# A31G33x register map
Vendor: VENDOR ABOV Semiconductor Co., Ltd.; Series: A31G33x; File version: 1.0
CPU: CM0+ r0p1, little endian, no MPU, no FPU, VTOR, 2 interrupt priority bits
Registers are 32-bit, read-only, no defined reset value unless marked. A register's access mark holds for its fields unless they carry their own. Offsets are from the block's base; [hi:lo] are bit positions.

## SCULV — System Control Unit: LVI and LVR
Base 0x40005100
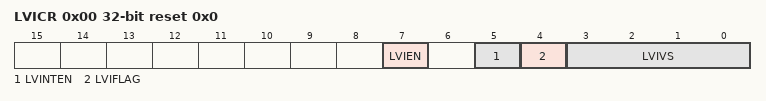
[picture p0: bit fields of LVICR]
0x00 LVICR rw reset 0x0 — Low Voltage Indicator Control Register
  [7] LVIEN — LVI Enable
    0=Disable low voltage indicator; 1=Enable low voltage indicator
  [5] LVINTEN — LVI Interrupt Enable
    0=Disable low voltage indicator interrupt; 1=Enable low voltage indicator interrupt
  [4] LVIFLAG — LVI Interrupt Flag
    0=No request occurred; 1=Request occurred
  [3:0] LVIVS — LVI Voltage Selection
    3=1p94 (1.94V); 4=2p03 (2.03V); 5=2p16V (2.16V); 6=2p35V (2.35V); 7=2p52V (2.52V); 8=2p72V (2.72V); 9=3p10V (3.10V); 10=3p24V (3.24V); 11=3p66V (3.66V); 12=3p79V (3.79V); 13=4p11V (4.11V); 14=4p28V (4.28V); 15=4p57V (4.57V)
0x04 LVRCR rw reset 0x0 — Low Voltage Reset Control Register
  [7:0] LVREN — LVR Enable
    85=Disable low voltage reset. (0x55); 0=Enable low voltage reset

## FMC — Flash Memory Controller
Base 0x40001B00
0x00 ADR rw reset 0x5FFFFF80 — Flash Memory Address Register
  [31:0] ADDR — Flash Memory Address Pointer
0x04 IDR1 rw reset 0x0 — Flash Memory Identification Register 1
  [31:0] ID1 — Flash Memory Identification 1
    0x8192A3B=Value (ID1 Value (0x08192a3b))
0x08 IDR2 rw reset 0x0 — Flash Memory Identification Register 2
  [31:0] ID2 — Flash Memory Identification 2
    0x4C5D6E7F=Value (ID2 Value (0x4c5d6e7f))
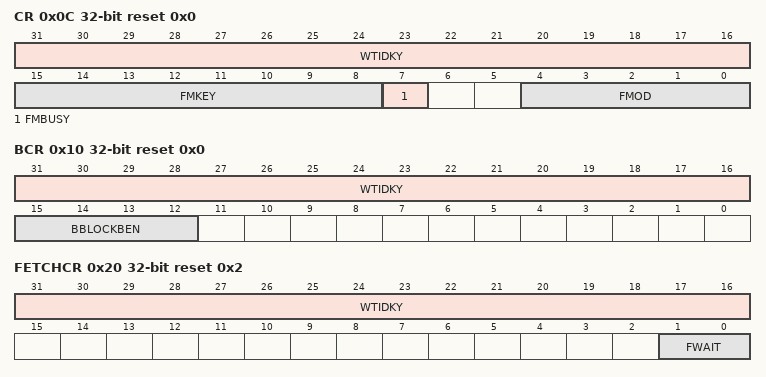
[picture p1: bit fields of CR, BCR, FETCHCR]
0x0C CR rw reset 0x0 — Flash Memory Control Register
  [31:16] WTIDKY wo — Write Identification Key (0x6c93)
    0x6C93=Value (Key Value (0x6c93))
  [15:8] FMKEY — Flash Memory Operation Area Selection
    0=NoSelect (Not select any area); 56=ConfigurationOptionArea (Select 'configure option area' for flash memory erase/write); 164=Flash (Select 'flash memory area' for flash memory erase/write)
  [7] FMBUSY ro — Flash Memory Operation Mode Busy
    0=NoEffect; 1=Busy
  [4:0] FMOD — Flash Memory Operation Mode Selection
    1=PageErase ('Flash page erase mode' and start when the flash operation rule is satisfied.); 2=SectorErase ('Flash sector erase mode' and start when the flash operation rule is satisfied.); 4=Write ('Flash write mode' and start when the flash operation rule is satisfied.); 8=BurstWrite ('Flash burst write mode' and start when the flash operation rule is satisfied.); 16=BulkErase ('Flash bulk erase mode' and start when the flash operation rule is satisfied.)
0x10 BCR rw reset 0x0 — Flash Memory Boot Protection Block Bulk Erase Control Register
  [31:16] WTIDKY wo — Write Identification Key (0xc1be)
    0xC1BE=Value (Key Value (0xc1be))
  [15:12] BBLOCKBEN — Boot Protection Block Bulk Erase Enable
    5=Enable (Permit 'boot protection block' erase when bulk erase)
0x14 ERFLAG rw reset 0x0 — Flash Memory Error Flag
  [0] FMOPFLAG — Error bit of Flash Memory Operation Procedure
    0=NoWrongProcedure; 1=WrongProcedure (A wrong procedure occurred, This bit is cleared to '0' when write '1'.)
0x20 FETCHCR rw reset 0x2 — Flash Memory Data Fetch Control Register
  [31:16] WTIDKY wo — Write Identification Key (0xd7a4)
    0xD7A4=Value (Key Value (0xd7a4))
  [1:0] FWAIT — Wait Fetch Mode Selection
    0=0-wait fetch mode (When system clock LE 20MHz); 1=1-wait fetch mode (When system clock LE 40MHz); 2=2-wait fetch mode (When system clock GT 40MHz); 3=3-wait fetch mode

## CRC — Cyclic Redundancy Check and Checksum
Base 0x30001000
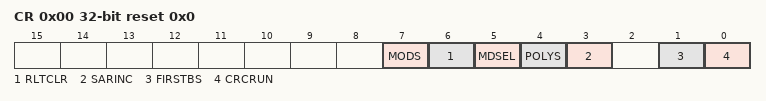
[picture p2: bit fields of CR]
0x00 CR rw reset 0x0 — CRC/Checksum Control Register
  [7] MODS — User/Auto Mode Selection
    0=User Mode (Calculate every data written to the CRC_IN register); 1=Auto Mode (Calculate till CRC_SADR == CRC_EADR)
  [6] RLTCLR — CRC/Checksum Result Data Register (CRC_RLT) Initialization
    0=NoEffect; 1=Initialize the CRC_RLT register with the value of CRC_INIT. (This bit is automatically cleared to '0' after operation.)
  [5] MDSEL — CRC/Checksum Selection
    0=CRC (Select CRC.); 1=Checksum (Select Checksum.)
  [4] POLYS — Polynomial Selection (CRC only)
    0=CRC16_CCITT (CRC16-CCITT (G1(x) = x16 + x12 + x5 + 1)); 1=CRC16 (CRC16 (G2(x) = x16 + x15 + x2 + 1))
  [3] SARINC — CRC/Checksum Start Address Auto Increment Control (User mode only)
    0=Disable (No effect.); 1=Enable (The CRC/Checksum start address register is incremented by '4' every writing to the CRC_IN register.)
  [1] FIRSTBS — First Shifted-in Selection (CRC only)
    0=msbFirst; 1=lsbFirst
  [0] CRCRUN — CRC/Checksum Start/Stop Control
    0=Stop (Not busy. The CRC operation can be finished by writing '0' to this bit while running.); 1=Start CRC operation. This bit is automatically cleared to '0' when the value of CRC_SADR register reaches the value of CRC_EADR register.
0x04 IN rw reset 0x0 — CRC/Checksum Input Data Register
  [31:0] INDATA — CRC Input Data
0x08 RLT reset 0xFFFF — CRC/Checksum Result Data Register
  [15:0] RLTDATA — CRC Result Data
0x0C INIT rw reset 0x0 — CRC/Checksum Initial Data Register
  [15:0] INIDATA — CRC Initial Data
0x10 SADR rw reset 0x10000000 — CRC/Checksum Start Address Register
  [31:2] SADR — CRC Start Address
0x14 EADR rw reset 0x1003FFFC — CRC/Checksum End Address Register
  [31:2] EADR — CRC End Address
